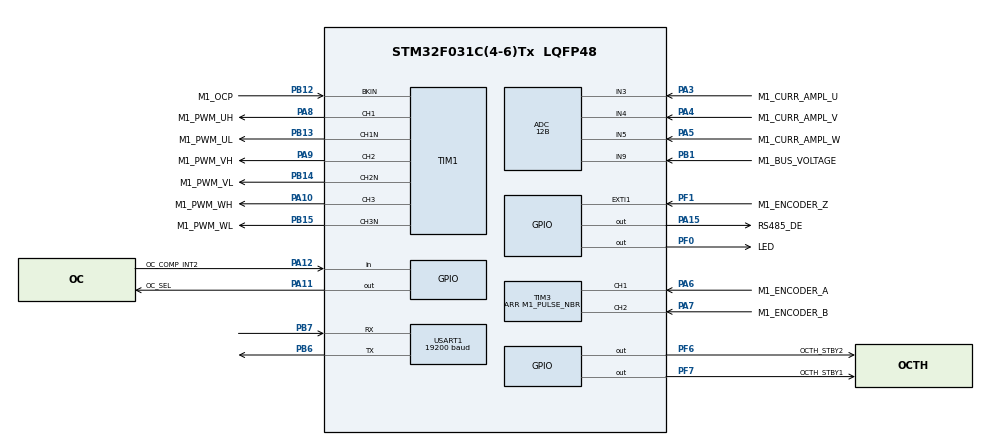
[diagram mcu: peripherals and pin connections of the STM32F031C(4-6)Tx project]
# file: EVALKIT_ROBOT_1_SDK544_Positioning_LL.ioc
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ADC.ClockPrescaler=ADC_CLOCK_ASYNC_DIV1
ADC.ContinuousConvMode=DISABLE
ADC.DMAContinuousRequests=ENABLE
ADC.DataAlign=ADC_DATAALIGN_LEFT
ADC.DiscontinuousConvMode=DISABLE
ADC.EOCSelection=ADC_EOC_SINGLE_CONV
ADC.EnableAnalogWatchDog=false
ADC.ExternalTrigConv=ADC_EXTERNALTRIGCONV_T1_TRGO
ADC.ExternalTrigConvEdge=ADC_EXTERNALTRIGCONVEDGE_RISING
ADC.LowPowerAutoPowerOff=DISABLE
ADC.LowPowerAutoWait=DISABLE
ADC.Overrun=ADC_OVR_DATA_PRESERVED
ADC.Resolution=ADC_RESOLUTION_12B
ADC.SamplingTime=ADC_SAMPLETIME_7CYCLES_5
ADC.ScanConvMode=ADC_SCAN_DIRECTION_FORWARD
Dma.ADC.0.Direction=DMA_PERIPH_TO_MEMORY
Dma.ADC.0.Instance=DMA1_Channel1
Dma.ADC.0.MemDataAlignment=DMA_MDATAALIGN_HALFWORD
Dma.ADC.0.MemInc=DMA_MINC_ENABLE
Dma.ADC.0.Mode=DMA_CIRCULAR
Dma.ADC.0.PeriphDataAlignment=DMA_PDATAALIGN_HALFWORD
Dma.ADC.0.PeriphInc=DMA_PINC_DISABLE
Dma.ADC.0.Priority=DMA_PRIORITY_HIGH
Dma.Request0=ADC
ExtraMW=MotorControl
ExtraMW.MotorControl.Config=MotorControl
ExtraMW.MotorControl.Mode=MotorControl
ExtraMW.MotorControl.Root=MCSDK_v5.4.4/MotorControl
ExtraMW.MotorControl.Template=templates
Mcu.Family=STM32F0
Mcu.Name=STM32F031C(4-6)Tx
Mcu.Package=LQFP48
MotorControl.ADC_1_PERIPH=ADC1
MotorControl.ADC_2_PERIPH=ADC2
MotorControl.ADC_AHBPERIPH=RCC_AHBPeriph_ADC12
MotorControl.ADC_CLOCK_WB_DIV=1
MotorControl.ADC_CLOCK_WB_FREQ=12
MotorControl.ADC_PERIPH=ADC1
MotorControl.ADC_REFERENCE_VOLTAGE=3.30
MotorControl.ALIGNMENT_ANGLE_DEG=0
MotorControl.ALIGNMENT_DURATION=700
MotorControl.AMPLIFICATION_GAIN=4.38
MotorControl.ANGC={0,0,0,0,0,0,0,0}
MotorControl.BEMF_CONSISTENCY_GAIN=64
MotorControl.BEMF_CONSISTENCY_TOL=64
MotorControl.BKIN1_FILTER=0
MotorControl.BKIN2_FILTER=0
MotorControl.BKIN2_MODE=NONE
MotorControl.BKIN_MODE=EXT_MODE
MotorControl.BOARD=CUSTOM
MotorControl.BRKIN2_GPIO_AF=GPIO_AF_2
MotorControl.BRKIN_GPIO_AF=GPIO_AF_2
MotorControl.BUS_VOLTAGE_READING=true
MotorControl.CCMRAM_ENABLED=false
MotorControl.CLOCK_FREQUENCY=CPU_CLK_48_MHZ
MotorControl.CLOCK_SOURCE=INTERNAL
MotorControl.CONSTANT1_D=25086
MotorControl.CONSTANT1_Q=25086
MotorControl.CONSTANT2_QD=17556
MotorControl.CORD_BEMF_CONSISTENCY_GAIN=64
MotorControl.CORD_BEMF_CONSISTENCY_TOL=64
MotorControl.CORD_F1=8192
MotorControl.CORD_F2=16384
MotorControl.CORD_FIFO_DEPTH_01HZ=64
MotorControl.CORD_FIFO_DEPTH_DPP=64
MotorControl.CORD_GAIN1=-11637
MotorControl.CORD_GAIN2=5027
MotorControl.CORD_MAX_ACCEL_DPPP=187
MotorControl.CORD_MEAS_ERRORS_BEFORE_FAULTS=3
MotorControl.CORD_VARIANCE_THRESHOLD=4
MotorControl.CPU_CLK_48_MHZ=true
MotorControl.CTRBDID=10010
MotorControl.CUBE_MX_VER=5.6.1
MotorControl.CURRENT_READING_TOPOLOGY=THREE_SHUNT
MotorControl.CURR_SAMPLING_TIME=7
MotorControl.DAC_EMULATED=false
MotorControl.DAC_FUNCTIONALITY=false
MotorControl.DAC_TIMER_CH1_GPIO_PIN=LL_GPIO_PIN_0
MotorControl.DAC_TIMER_CH1_GPIO_PORT=GPIOA
MotorControl.DAC_TIMER_CH2_GPIO_PIN=LL_GPIO_PIN_0
MotorControl.DAC_TIMER_CH2_GPIO_PORT=GPIOA
MotorControl.DAC_TIMER_SELECTION=TIM14
MotorControl.DC_CURRENT_RS_MEAS=2.72
MotorControl.DEBUG_DAC_CH1=false
MotorControl.DEBUG_DAC_CH2=false
MotorControl.DEFAULT_CONTROL_MODE=STC_SPEED_MODE
MotorControl.DEFAULT_DAC_CHANNEL_1=MC_PROTOCOL_REG_I_A
MotorControl.DEFAULT_DAC_CHANNEL_2=MC_PROTOCOL_REG_I_B
MotorControl.DEFAULT_DAC_MOTOR=0
MotorControl.DEFAULT_FLUX_COMPONENT=0
MotorControl.DEFAULT_TARGET_SPEED_RPM=500
MotorControl.DEFAULT_TORQUE_COMPONENT=0
MotorControl.DISSIPATIVE_BRAKE_POLARITY=DOUT_ACTIVE_HIGH
MotorControl.DRIVES_NUMBER_SELECTION=SINGLEDRIVE
MotorControl.EMERGENCY2_STOP_GPIO_PIN=LL_GPIO_PIN_12
MotorControl.EMERGENCY2_STOP_GPIO_PORT=GPIOB
MotorControl.EMERGENCY_STOP_GPIO_PIN=LL_GPIO_PIN_12
MotorControl.EMERGENCY_STOP_GPIO_PORT=GPIOB
MotorControl.ENABLE_SL_ALGO_FROM_PHASE=2
MotorControl.ENCODER=true
MotorControl.ENCODER_AVAILABLE=true
MotorControl.ENCODER_PPR=1024
MotorControl.ENC_AVERAGING_FIFO_DEPTH=16
MotorControl.ENC_A_GPIO_PIN=LL_GPIO_PIN_6
MotorControl.ENC_A_GPIO_PORT=GPIOA
MotorControl.ENC_B_GPIO_PIN=LL_GPIO_PIN_7
MotorControl.ENC_B_GPIO_PORT=GPIOA
MotorControl.ENC_ICx_FILTER=32
MotorControl.ENC_INVERT_SPEED=false
MotorControl.ENC_MEAS_ERRORS_BEFORE_FAULTS=3
MotorControl.ENC_TIMER_REMAPPING=NO_REMAP_TIM3
MotorControl.ENC_TIMER_SELECTION=ENC_TIM3
MotorControl.ENC_USE_CH3=true
MotorControl.ENC_Z_GPIO_PIN=LL_GPIO_PIN_0
MotorControl.ENC_Z_GPIO_PORT=GPIOB
MotorControl.EXT_CLOCK_FREQUENCY=INT_RC_OSC
MotorControl.F1=8192
MotorControl.F2=16384
MotorControl.FEEDBACK_NET_FILTERING=false
MotorControl.FEED_FORWARD_CURRENT_REG_ENABLING=false
MotorControl.FINAL_I_ALIGNMENT=13047
MotorControl.FLUX_WEAKENING_ENABLING=false
MotorControl.FW_KIDIV=32768
MotorControl.FW_KI_GAIN=5000
MotorControl.FW_KPDIV=32768
MotorControl.FW_KP_GAIN=3000
MotorControl.FW_VOLTAGE_REF=985
MotorControl.GAIN1=-11637
MotorControl.GAIN2=5027
MotorControl.H1_GPIO_PIN=LL_GPIO_PIN_0
MotorControl.H1_GPIO_PORT=GPIOA
MotorControl.H2_GPIO_PIN=LL_GPIO_PIN_1
MotorControl.H2_GPIO_PORT=GPIOA
MotorControl.H3_GPIO_PIN=LL_GPIO_PIN_2
MotorControl.H3_GPIO_PORT=GPIOA
MotorControl.HALL_AVERAGING_FIFO_DEPTH=6
MotorControl.HALL_ICx_FILTER=62
MotorControl.HALL_MEAS_ERRORS_BEFORE_FAULTS=3
MotorControl.HALL_MTPA=false
MotorControl.HALL_PHASE_SHIFT=300
MotorControl.HALL_SENSORS_AVAILABLE=true
MotorControl.HALL_SENSORS_PLACEMENT=DEGREES_120
MotorControl.HALL_TIMER_REMAPPING=NO_REMAP_TIM2
MotorControl.HALL_TIMER_SELECTION=HALL_TIM2
MotorControl.HFI_AMPLITUDE=25
MotorControl.HFI_DC_0_COEFF=0.00146
MotorControl.HFI_DC_1_COEFF=0.002921
MotorControl.HFI_DC_2_COEFF=0.00146
MotorControl.HFI_DC_3_COEFF=1.889033
MotorControl.HFI_DC_4_COEFF=-0.894874
MotorControl.HFI_DEBUG_MODE=false
MotorControl.HFI_FREQUENCY=400
MotorControl.HFI_HIFRAMPLSCAN=25
MotorControl.HFI_HP_ID_0_COEFF=0.901513
MotorControl.HFI_HP_ID_1_COEFF=-1.803026
MotorControl.HFI_HP_ID_2_COEFF=0.901513
MotorControl.HFI_HP_ID_3_COEFF=1.793303
MotorControl.HFI_HP_ID_4_COEFF=-0.81275
MotorControl.HFI_IDH_DELAY=32400
MotorControl.HFI_LOCKFREQ=55
MotorControl.HFI_LP_ID_0_COEFF=0.015476
MotorControl.HFI_LP_ID_1_COEFF=0.030952
MotorControl.HFI_LP_ID_2_COEFF=0.015476
MotorControl.HFI_LP_ID_3_COEFF=1.61855
MotorControl.HFI_LP_ID_4_COEFF=-0.680453
MotorControl.HFI_MAXANGLEDIFF=3640
MotorControl.HFI_MINIMUM_SPEED_RPM=402
MotorControl.HFI_NOTCH_IQD_0_COEFF=0.95059
MotorControl.HFI_NOTCH_IQD_1_COEFF=-1.859635
MotorControl.HFI_NOTCH_IQD_2_COEFF=0.95059
MotorControl.HFI_NOTCH_IQD_3_COEFF=1.859635
MotorControl.HFI_NOTCH_IQD_4_COEFF=-0.901181
MotorControl.HFI_NSDETPOINTSSKIP=10
MotorControl.HFI_NSMAXDETPOINTS=20
MotorControl.HFI_NS_MIN_SAT_DIFF=0
MotorControl.HFI_PID_KIDIV=32768
MotorControl.HFI_PID_KI_DEFAULT=400
MotorControl.HFI_PID_KPDIV=16384
MotorControl.HFI_PID_KP_DEFAULT=800
MotorControl.HFI_PLL_KI_DEFAULT=0.00400
MotorControl.HFI_PLL_KP_DEFAULT=0.00060
MotorControl.HFI_RESTARTTIMESEC=0.1
MotorControl.HFI_RESTART_RPM_TH=(((HFI_STO_RPM_TH)+(STO_HFI_RPM_TH))/2)
MotorControl.HFI_REVERT_DIRECTION=true
MotorControl.HFI_SCANROTATIONSNO=3
MotorControl.HFI_SPD_BUFFER_DEPTH_01HZ=64
MotorControl.HFI_STEPANGLE=3640
MotorControl.HFI_STO_RPM_TH=OBS_MINIMUM_SPEED_RPM
MotorControl.HFI_WAITAFTERNS2=4
MotorControl.HFI_WAITBEFORESN=6
MotorControl.HFI_WAITSYNCH=20
MotorControl.HFI_WAITTRACK=20
MotorControl.HIGH_SIDE_BRAKE_STATE=false
MotorControl.HIGH_SIDE_IDLE_STATE=false
MotorControl.HW_COMPLEMENTED_LOW_SIDE=false
MotorControl.HW_DEAD_TIME_NS=100
MotorControl.HW_OV_CURRENT_PROT_BYPASS=false
MotorControl.ID_DEMAG=-23658
MotorControl.INRUSH_CURRLIMIT_AT_POWER_ON=true
MotorControl.INRUSH_CURRLIMIT_CHANGE_AFTER_MS=1000
MotorControl.INRUSH_CURRLIMIT_ENABLING=false
MotorControl.INRUSH_CURRLIMIT_GPIO_PIN=LL_GPIO_PIN_4
MotorControl.INRUSH_CURRLIMIT_GPIO_PORT=GPIOE
MotorControl.INRUSH_CURR_LIMITER_POLARITY=DOUT_ACTIVE_HIGH
MotorControl.INTERNAL_OVERCURRENTPROTECTION=false
MotorControl.INTERNAL_OVERVOLTAGEPROTECTION=false
MotorControl.INT_RC_OSC=true
MotorControl.IPs=NVIC,RCC,SYS,MotorControl,TIM1,ADC,DMA,TIM3
MotorControl.IQMAX=23658
MotorControl.LCD_JOYSTICK_FUNCTIONALITY=false
MotorControl.LCD_MODE=LCD_FULL
MotorControl.LDLQ_RATIO=1.000
MotorControl.LOW_SIDE_BRAKE_STATE=false
MotorControl.LOW_SIDE_IDLE_STATE=false
MotorControl.LOW_SIDE_SIGNALS_ENABLING=LS_PWM_TIMER
MotorControl.LS=0.000338
MotorControl.MAX_APPLICATION_SPEED=4550
MotorControl.MAX_MODULATION_100_PER_CENT=true
MotorControl.MAX_MODULATION_INDEX=MAX_MODULATION_100_PER_CENT
MotorControl.MCU=STSPIN32F0A
MotorControl.MCU_TYPE=STSPIN32F0A
MotorControl.MC_WORKBENCH_VERSION=5.4.4.20160
MotorControl.MEAS_ERRORS_BEFORE_FAULTS=3
MotorControl.MIN_APPLICATION_SPEED=0
MotorControl.MOTOR_MAX_SPEED_RPM=4550
MotorControl.MOTOR_TYPE=PMSM
MotorControl.MOTOR_VOLTAGE_CONSTANT=6.4
MotorControl.MTPA_ENABLING=false
MotorControl.NB_CONSECUTIVE_TESTS=2
MotorControl.NOMINAL_BUS_VOLTAGE_V=36
MotorControl.NOMINAL_CURRENT=23658
MotorControl.OBS_MEAS_ERRORS_BEFORE_FAULTS=3
MotorControl.OBS_MINIMUM_SPEED_RPM=886
MotorControl.OCPA_INVERTINGINPUT=COMPX_InvertingInput_VREF
MotorControl.OCPA_INVERTINGINPUT_GPIO_PIN=LL_GPIO_PIN_4
MotorControl.OCPA_INVERTINGINPUT_GPIO_PORT=GPIOA
MotorControl.OCPA_INVERTINGINPUT_MODE=INT_MODE
MotorControl.OCPA_NONINVERTINGINPUT=COMP1_NonInvertingInput_PA1
MotorControl.OCPA_NONINVERTINGINPUT_GPIO_PIN=LL_GPIO_PIN_1
MotorControl.OCPA_NONINVERTINGINPUT_GPIO_PORT=GPIOA
MotorControl.OCPA_OUTPUT=COMP_Output_TIM1BKIN2
MotorControl.OCPA_OUTPUTPOL=COMP_OutputPol_NonInverted
MotorControl.OCPA_OUTPUT_GPIO_AF=GPIO_AF_2
MotorControl.OCPA_OUTPUT_GPIO_PIN=LL_GPIO_PIN_0
MotorControl.OCPA_OUTPUT_GPIO_PORT=GPIOA
MotorControl.OCPA_OUTPUT_MODE=INT_MODE
MotorControl.OCPA_SELECTION=COMP1
MotorControl.OCPB_INVERTINGINPUT=COMPX_InvertingInput_VREF
MotorControl.OCPB_INVERTINGINPUT_GPIO_PIN=LL_GPIO_PIN_4
MotorControl.OCPB_INVERTINGINPUT_GPIO_PORT=GPIOA
MotorControl.OCPB_INVERTINGINPUT_MODE=INT_MODE
MotorControl.OCPB_NONINVERTINGINPUT=COMP2_NonInvertingInput_PA7
MotorControl.OCPB_NONINVERTINGINPUT_GPIO_PIN=LL_GPIO_PIN_7
MotorControl.OCPB_NONINVERTINGINPUT_GPIO_PORT=GPIOA
MotorControl.OCPB_OUTPUT=COMP_Output_TIM1BKIN2
MotorControl.OCPB_OUTPUTPOL=COMP_OutputPol_NonInverted
MotorControl.OCPB_OUTPUT_GPIO_AF=GPIO_AF_2
MotorControl.OCPB_OUTPUT_GPIO_PIN=LL_GPIO_PIN_2
MotorControl.OCPB_OUTPUT_GPIO_PORT=GPIOA
MotorControl.OCPB_OUTPUT_MODE=INT_MODE
MotorControl.OCPB_SELECTION=COMP2
MotorControl.OCPC_INVERTINGINPUT=COMPX_InvertingInput_VREF
MotorControl.OCPC_INVERTINGINPUT_GPIO_PIN=LL_GPIO_PIN_4
MotorControl.OCPC_INVERTINGINPUT_GPIO_PORT=GPIOA
MotorControl.OCPC_INVERTINGINPUT_MODE=INT_MODE
MotorControl.OCPC_NONINVERTINGINPUT=COMP3_NonInvertingInput_PB14
MotorControl.OCPC_NONINVERTINGINPUT_GPIO_PIN=LL_GPIO_PIN_14
MotorControl.OCPC_NONINVERTINGINPUT_GPIO_PORT=GPIOB
MotorControl.OCPC_OUTPUT=COMP_Output_TIM1BKIN2
MotorControl.OCPC_OUTPUTPOL=COMP_OutputPol_NonInverted
MotorControl.OCPC_OUTPUT_GPIO_AF=GPIO_AF_2
MotorControl.OCPC_OUTPUT_GPIO_PIN=LL_GPIO_PIN_8
MotorControl.OCPC_OUTPUT_GPIO_PORT=GPIOC
MotorControl.OCPC_OUTPUT_MODE=INT_MODE
MotorControl.OCPC_SELECTION=COMP3
MotorControl.OCPREF=23830
MotorControl.OCP_COMP_THRESHOLD=0.50
MotorControl.OCP_FILTER=COMP_Mode_HighSpeed
MotorControl.OCP_INVERTINGINPUT=COMPX_InvertingInput_VREF
MotorControl.OCP_INVERTINGINPUT_GPIO_PIN=LL_GPIO_PIN_4
MotorControl.OCP_INVERTINGINPUT_GPIO_PORT=GPIOA
MotorControl.OCP_INVERTINGINPUT_MODE=INT_MODE
MotorControl.OCP_NONINVERTINGINPUT=COMP2_NonInvertingInput_PA7
MotorControl.OCP_NONINVERTINGINPUT_GPIO_PIN=LL_GPIO_PIN_7
MotorControl.OCP_NONINVERTINGINPUT_GPIO_PORT=GPIOA
MotorControl.OCP_OUTPUT=COMP_Output_TIM1BKIN2
MotorControl.OCP_OUTPUTPOL=COMP_OutputPol_NonInverted
MotorControl.OCP_OUTPUT_GPIO_AF=GPIO_AF_2
MotorControl.OCP_OUTPUT_GPIO_PIN=LL_GPIO_PIN_2
MotorControl.OCP_OUTPUT_GPIO_PORT=GPIOA
MotorControl.OCP_OUTPUT_MODE=INT_MODE
MotorControl.OCP_SELECTION=COMP2
MotorControl.OFST={0,0,0,0,0,0,0,0}
MotorControl.ON_OVER_VOLTAGE=TURN_OFF_PWM
MotorControl.OPAMP1_INVERTINGINPUT=OPAMP1_InvertingInput_PGA
MotorControl.OPAMP1_INVERTINGINPUT_GPIO_PIN=LL_GPIO_PIN_3
MotorControl.OPAMP1_INVERTINGINPUT_GPIO_PORT=GPIOA
MotorControl.OPAMP1_INVERTINGINPUT_MODE=INT_MODE
MotorControl.OPAMP1_NONINVERTINGINPUT_PHA=OPAMP1_NonInvertingInput_PA1
MotorControl.OPAMP1_NONINVERTINGINPUT_PHA_GPIO_PIN=LL_GPIO_PIN_1
MotorControl.OPAMP1_NONINVERTINGINPUT_PHA_GPIO_PORT=GPIOA
MotorControl.OPAMP1_NONINVERTINGINPUT_PHB=OPAMP1_NonInvertingInput_PA7
MotorControl.OPAMP1_NONINVERTINGINPUT_PHB_GPIO_PIN=LL_GPIO_PIN_7
MotorControl.OPAMP1_NONINVERTINGINPUT_PHB_GPIO_PORT=GPIOA
MotorControl.OPAMP1_OUT_GPIO_PIN=LL_GPIO_PIN_2
MotorControl.OPAMP1_OUT_GPIO_PORT=GPIOA
MotorControl.OPAMP1_SELECTION=OPAMP1
MotorControl.OPAMP2_INVERTINGINPUT=OPAMP2_InvertingInput_PGA
MotorControl.OPAMP2_INVERTINGINPUT_GPIO_PIN=LL_GPIO_PIN_5
MotorControl.OPAMP2_INVERTINGINPUT_GPIO_PORT=GPIOC
MotorControl.OPAMP2_INVERTINGINPUT_MODE=INT_MODE
MotorControl.OPAMP2_NONINVERTINGINPUT_PHA=OPAMP2_NonInvertingInput_PB14
MotorControl.OPAMP2_NONINVERTINGINPUT_PHA_GPIO_PIN=LL_GPIO_PIN_14
MotorControl.OPAMP2_NONINVERTINGINPUT_PHA_GPIO_PORT=GPIOB
MotorControl.OPAMP2_NONINVERTINGINPUT_PHB=OPAMP2_NonInvertingInput_PA7
MotorControl.OPAMP2_NONINVERTINGINPUT_PHB_GPIO_PIN=LL_GPIO_PIN_7
MotorControl.OPAMP2_NONINVERTINGINPUT_PHB_GPIO_PORT=GPIOA
MotorControl.OPAMP2_NONINVERTINGINPUT_PHC=OPAMP2_NonInvertingInput_PB14
MotorControl.OPAMP2_NONINVERTINGINPUT_PHC_GPIO_PIN=LL_GPIO_PIN_14
MotorControl.OPAMP2_NONINVERTINGINPUT_PHC_GPIO_PORT=GPIOB
MotorControl.OPAMP2_OUT_GPIO_PIN=LL_GPIO_PIN_6
MotorControl.OPAMP2_OUT_GPIO_PORT=GPIOA
MotorControl.OPAMP2_SELECTION=OPAMP2
MotorControl.OPAMP3_INVERTINGINPUT=OPAMP1_InvertingInput_PGA
MotorControl.OPAMP3_INVERTINGINPUT_GPIO_PIN=LL_GPIO_PIN_0
MotorControl.OPAMP3_INVERTINGINPUT_GPIO_PORT=GPIOA
MotorControl.OPAMP3_INVERTINGINPUT_MODE=INT_MODE
MotorControl.OPAMP3_SELECTION=OPAMP1
MotorControl.OPAMP_INVERTINGINPUT=OPAMP1_InvertingInput_PGA
MotorControl.OPAMP_INVERTINGINPUT_GPIO_PIN=LL_GPIO_PIN_3
MotorControl.OPAMP_INVERTINGINPUT_GPIO_PORT=GPIOA
MotorControl.OPAMP_INVERTINGINPUT_MODE=INT_MODE
MotorControl.OPAMP_NONINVERTINGINPUT=OPAMP1_NonInvertingInput_PA7
MotorControl.OPAMP_NONINVERTINGINPUT_GPIO_PIN=LL_GPIO_PIN_7
MotorControl.OPAMP_NONINVERTINGINPUT_GPIO_PORT=GPIOA
MotorControl.OPAMP_OUT_GPIO_PIN=LL_GPIO_PIN_2
MotorControl.OPAMP_OUT_GPIO_PORT=GPIOA
MotorControl.OPAMP_PGACONNECT=OPAMP_PGAConnect_No
MotorControl.OPAMP_PGAGAIN=OPAMP_OPAMP_PGAGain_2
MotorControl.OPAMP_SELECTION=OPAMP1
MotorControl.OPAMP_TYPE_GAIN=INTERNAL
MotorControl.OPEN_LOOP_FOC=false
MotorControl.OPEN_LOOP_K=44
MotorControl.OPEN_LOOP_OFF=4400
MotorControl.OPEN_LOOP_SPEED_RAMP_DURATION_MS=1000
MotorControl.OPEN_LOOP_SPEED_RPM=100
MotorControl.OPEN_LOOP_VF=false
MotorControl.OPEN_LOOP_VOLTAGE_d=6000
MotorControl.OVERCURR_FEEDBACK_POLARITY=EMSTOP_ACTIVE_HIGH
MotorControl.OVERCURR_PROTECTION_HW_DISABLING=DOUT_ACTIVE_HIGH
MotorControl.OVPREF=23830
MotorControl.OVP_FILTER=COMP_Mode_HighSpeed
MotorControl.OVP_INVERTINGINPUT=COMPX_InvertingInput_VREF
MotorControl.OVP_INVERTINGINPUT_GPIO_PIN=LL_GPIO_PIN_4
MotorControl.OVP_INVERTINGINPUT_GPIO_PORT=GPIOA
MotorControl.OVP_INVERTINGINPUT_MODE=INT_MODE
MotorControl.OVP_NONINVERTINGINPUT=COMP7_NonInvertingInput_PA0
MotorControl.OVP_NONINVERTINGINPUT_GPIO_PIN=LL_GPIO_PIN_0
MotorControl.OVP_NONINVERTINGINPUT_GPIO_PORT=GPIOA
MotorControl.OVP_OUTPUT=COMP_Output_TIM1BKIN
MotorControl.OVP_OUTPUTPOL=COMP_OutputPol_NonInverted
MotorControl.OVP_OUTPUT_GPIO_AF=GPIO_AF_2
MotorControl.OVP_OUTPUT_GPIO_PIN=LL_GPIO_PIN_2
MotorControl.OVP_OUTPUT_GPIO_PORT=GPIOC
MotorControl.OVP_OUTPUT_MODE=INT_MODE
MotorControl.OVP_SELECTION=COMP7
MotorControl.OV_CURR_BYPASS_GPIO_PIN=LL_GPIO_PIN_5
MotorControl.OV_CURR_BYPASS_GPIO_PORT=GPIOE
MotorControl.OV_TEMPERATURE_HYSTERESIS_C=10
MotorControl.OV_TEMPERATURE_PROT_ENABLING=false
MotorControl.OV_TEMPERATURE_THRESHOLD_C=70
MotorControl.OV_VOLTAGE_PROT_ENABLING=true
MotorControl.OV_VOLTAGE_THRESHOLD_V=44
MotorControl.PHASE1_DURATION=1000
MotorControl.PHASE1_FINAL_CURRENT=13047
MotorControl.PHASE1_FINAL_SPEED_RPM=0
MotorControl.PHASE2_DURATION=1968
MotorControl.PHASE2_FINAL_CURRENT=13047
MotorControl.PHASE2_FINAL_SPEED_RPM=984
MotorControl.PHASE3_DURATION=0
MotorControl.PHASE3_FINAL_CURRENT=13047
MotorControl.PHASE3_FINAL_SPEED_RPM=984
MotorControl.PHASE4_DURATION=0
MotorControl.PHASE4_FINAL_CURRENT=13047
MotorControl.PHASE4_FINAL_SPEED_RPM=984
MotorControl.PHASE5_DURATION=0
MotorControl.PHASE5_FINAL_CURRENT=13047
MotorControl.PHASE5_FINAL_SPEED_RPM=984
MotorControl.PHASE_CURRENTS_ADC=ADC1_2
MotorControl.PHASE_CURRENTS_CHANNEL=ADC_CHANNEL_9
MotorControl.PHASE_CURRENTS_GPIO_PIN=LL_GPIO_PIN_0
MotorControl.PHASE_CURRENTS_GPIO_PORT=GPIOA
MotorControl.PHASE_UH_GPIO_AF=GPIO_AF_2
MotorControl.PHASE_UH_GPIO_PIN=LL_GPIO_PIN_8
MotorControl.PHASE_UH_GPIO_PORT=GPIOA
MotorControl.PHASE_UH_POLARITY=H_ACTIVE_HIGH
MotorControl.PHASE_UL_GPIO_AF=GPIO_AF_2
MotorControl.PHASE_UL_GPIO_PIN=LL_GPIO_PIN_13
MotorControl.PHASE_UL_GPIO_PORT=GPIOB
MotorControl.PHASE_UL_POLARITY=L_ACTIVE_HIGH
MotorControl.PHASE_U_CURR_ADC=ADC1
MotorControl.PHASE_U_CURR_CHANNEL=ADC_CHANNEL_3
MotorControl.PHASE_U_GPIO_PIN=LL_GPIO_PIN_3
MotorControl.PHASE_U_GPIO_PORT=GPIOA
MotorControl.PHASE_VH_GPIO_AF=GPIO_AF_2
MotorControl.PHASE_VH_GPIO_PIN=LL_GPIO_PIN_9
MotorControl.PHASE_VH_GPIO_PORT=GPIOA
MotorControl.PHASE_VH_POLARITY=H_ACTIVE_HIGH
MotorControl.PHASE_VL_GPIO_AF=GPIO_AF_2
MotorControl.PHASE_VL_GPIO_PIN=LL_GPIO_PIN_14
MotorControl.PHASE_VL_GPIO_PORT=GPIOB
MotorControl.PHASE_VL_POLARITY=L_ACTIVE_HIGH
MotorControl.PHASE_V_CURR_ADC=ADC1
MotorControl.PHASE_V_CURR_CHANNEL=ADC_CHANNEL_4
MotorControl.PHASE_V_GPIO_PIN=LL_GPIO_PIN_4
MotorControl.PHASE_V_GPIO_PORT=GPIOA
MotorControl.PHASE_WH_GPIO_AF=GPIO_AF_2
MotorControl.PHASE_WH_GPIO_PIN=LL_GPIO_PIN_10
MotorControl.PHASE_WH_GPIO_PORT=GPIOA
MotorControl.PHASE_WH_POLARITY=H_ACTIVE_HIGH
MotorControl.PHASE_WL_GPIO_AF=GPIO_AF_2
MotorControl.PHASE_WL_GPIO_PIN=LL_GPIO_PIN_15
MotorControl.PHASE_WL_GPIO_PORT=GPIOB
MotorControl.PHASE_WL_POLARITY=L_ACTIVE_HIGH
MotorControl.PHASE_W_CURR_ADC=ADC1
MotorControl.PHASE_W_CURR_CHANNEL=ADC_CHANNEL_5
MotorControl.PHASE_W_GPIO_PIN=LL_GPIO_PIN_5
MotorControl.PHASE_W_GPIO_PORT=GPIOA
MotorControl.PID_FLUX_KD_DEFAULT=100
MotorControl.PID_FLUX_KI_DEFAULT=246
MotorControl.PID_FLUX_KP_DEFAULT=2318
MotorControl.PID_SPEED_KD_DEFAULT=0
MotorControl.PID_SPEED_KI_DEFAULT=960
MotorControl.PID_SPEED_KP_DEFAULT=2902
MotorControl.PID_TORQUE_KD_DEFAULT=100
MotorControl.PID_TORQUE_KI_DEFAULT=246
MotorControl.PID_TORQUE_KP_DEFAULT=2318
MotorControl.PLL_KI_GAIN=83
MotorControl.PLL_KP_GAIN=1412
MotorControl.POLE_PAIR_NUM=7
MotorControl.POSITION_CTRL_ENABLING=true
MotorControl.POSITION_CTRL_KDDIV=16
MotorControl.POSITION_CTRL_KD_GAIN=1000
MotorControl.POSITION_CTRL_KIDIV=32768
MotorControl.POSITION_CTRL_KI_GAIN=1000
MotorControl.POSITION_CTRL_KPDIV=1024
MotorControl.POSITION_CTRL_KP_GAIN=10000
MotorControl.POSITION_LOOP_FREQUENCY_HZ=1000
MotorControl.PWBDID=10010
MotorControl.PWM_FREQUENCY=12000
MotorControl.PWM_TIMER_REMAPPING=PWM_NO_REMAP
MotorControl.PWM_TIMER_SELECTION=PWM_TIM1
MotorControl.REGCONVADC=ADC1
MotorControl.REGULATION_EXECUTION_RATE=1
MotorControl.RS=0.43
MotorControl.RSHUNT=0.10000
MotorControl.RTOS=NONE
MotorControl.R_BRAKE_GPIO_PIN=LL_GPIO_PIN_5
MotorControl.R_BRAKE_GPIO_PORT=GPIOE
MotorControl.R_BRAKE_SWITCH_OFF_THRES_V=35
MotorControl.SEGDIV=0
MotorControl.SERIAL_COMMUNICATION=false
MotorControl.SERIAL_COM_CHANNEL1=MC_PROTOCOL_REG_I_A
MotorControl.SERIAL_COM_CHANNEL2=MC_PROTOCOL_REG_I_A
MotorControl.SERIAL_COM_MODE=COM_BIDIRECTIONAL
MotorControl.SERIAL_COM_MOTOR=0
MotorControl.SHARED_SIGNAL_ENABLE=false
MotorControl.SINGLEDRIVE=true
MotorControl.SPD_DIFFERENTIAL_TERM_ENABLING=false
MotorControl.SPEED_BAND_LOWER_LIMIT=15
MotorControl.SPEED_BAND_UPPER_LIMIT=17
MotorControl.SPEED_SENSOR_SELECTION=ENCODER
MotorControl.SP_KDDIV=16
MotorControl.SP_KIDIV=16384
MotorControl.SP_KPDIV=128
MotorControl.STARTING_ANGLE_DEG=0
MotorControl.START_STOP_BTN=false
MotorControl.START_STOP_GPIO_PIN=LL_GPIO_PIN_0
MotorControl.START_STOP_GPIO_PORT=GPIOF
MotorControl.START_STOP_POLARITY=DIN_ACTIVE_LOW
MotorControl.START_STOP_POLARITY_EDGE=GPIO_PULLUP
MotorControl.STO_FIFO_DEPTH_01HZ=64
MotorControl.STO_FIFO_DEPTH_DPP=64
MotorControl.STO_HFI_RPM_TH=460
MotorControl.STSPIN32F0A=true
MotorControl.SW_DEADTIME_NS=300
MotorControl.SW_OV_CURRENT_PROT_ENABLING=true
MotorControl.T0_C=25
MotorControl.TEMPERATURE_READING=false
MotorControl.TEMP_ADC_SAMPLING_TIME=1
MotorControl.TEMP_FDBK_ADC=ADC1
MotorControl.TEMP_FDBK_CHANNEL=ADC_CHANNEL_5
MotorControl.TEMP_FDBK_GPIO_PIN=LL_GPIO_PIN_5
MotorControl.TEMP_FDBK_GPIO_PORT=GPIOA
MotorControl.TFDIFFERENTIAL_TERM_ENABLING=false
MotorControl.TF_KDDIV=8192
MotorControl.TF_KIDIV=16384
MotorControl.TF_KPDIV=16384
MotorControl.THREE_SHUNT=true
MotorControl.TNOISE_NS=800
MotorControl.TRANSITION_DURATION=25
MotorControl.TRISE_NS=800
MotorControl.T_MAX=70
MotorControl.UD_VOLTAGE_THRESHOLD_V=28
MotorControl.USART_REMAPPING=NO_REMAP_USART1
MotorControl.USART_RX_GPIO_PIN=LL_GPIO_PIN_7
MotorControl.USART_RX_GPIO_PORT=GPIOB
MotorControl.USART_SELECTION=USE_USART1
MotorControl.USART_SPEED=9600
MotorControl.USART_TX_GPIO_PIN=LL_GPIO_PIN_6
MotorControl.USART_TX_GPIO_PORT=GPIOB
MotorControl.USE_3OPAMPS=false
MotorControl.USE_INTERNAL_OPAMP=false
MotorControl.UV_VOLTAGE_PROT_ENABLING=true
MotorControl.V0_V=0.290
MotorControl.VARIANCE_THRESHOLD=0.1
MotorControl.VBUS_ADC=ADC1
MotorControl.VBUS_ADC_SAMPLING_TIME=28
MotorControl.VBUS_CHANNEL=ADC_CHANNEL_9
MotorControl.VBUS_GPIO_PIN=LL_GPIO_PIN_1
MotorControl.VBUS_GPIO_PORT=GPIOB
MotorControl.VBUS_PARTITIONING_FACTOR=0.0526
MotorControl.WB_to_Mx_template_version=20-04-17
MotorControl.WB_to_Mx_version=1.1.0
MotorControl.dV_dT=0.025
NVIC.DMA1_Channel1_IRQn=true\:1\:0\:true\:true\:false\:2\:true\:true
NVIC.EXTI0_1_IRQn=true\:3\:0\:false\:true\:false\:4\:true\:true
NVIC.TIM14_IRQn=true\:2\:0\:true\:true\:true\:5\:true\:false
NVIC.TIM16_IRQn=true\:2\:0\:true\:true\:true\:6\:true\:false
NVIC.TIM1_BRK_UP_TRG_COM_IRQn=true\:0\:0\:false\:true\:false\:1\:true\:true
NVIC.TIM3_IRQn=true\:3\:0\:false\:true\:false\:3\:true\:true
NVIC.USART1_IRQn=true\:3\:0\:true\:true\:true\:7\:true\:false
PA10.GPIO_Label=M1_PWM_WH
PA10.GPIO_PuPd=GPIO_PULLDOWN
PA10.GPIO_Speed=GPIO_SPEED_FREQ_HIGH
PA10.Signal=S_TIM1_CH3
PA11.GPIO_Label=OC_SEL
PA11.GPIO_PuPd=GPIO_PULLDOWN
PA11.PinState=GPIO_PIN_SET
PA11.Signal=GPIO_Output
PA12.GPIO_Label=OC_COMP_INT2
PA12.GPIO_PuPd=GPIO_PULLDOWN
PA12.Signal=GPIO_Input
PA15.GPIO_Label=RS485_DE
PA15.Signal=GPIO_Output
PA3.GPIO_Label=M1_CURR_AMPL_U
PA3.Mode=IN3
PA3.Signal=ADC_IN3
PA4.GPIO_Label=M1_CURR_AMPL_V
PA4.Mode=IN4
PA4.Signal=ADC_IN4
PA5.GPIO_Label=M1_CURR_AMPL_W
PA5.Mode=IN5
PA5.Signal=ADC_IN5
PA6.GPIO_Label=M1_ENCODER_A
PA6.Signal=S_TIM3_CH1
PA7.GPIO_Label=M1_ENCODER_B
PA7.Signal=S_TIM3_CH2
PA8.GPIO_Label=M1_PWM_UH
PA8.GPIO_PuPd=GPIO_PULLDOWN
PA8.GPIO_Speed=GPIO_SPEED_FREQ_HIGH
PA8.Signal=S_TIM1_CH1
PA9.GPIO_Label=M1_PWM_VH
PA9.GPIO_PuPd=GPIO_PULLDOWN
PA9.GPIO_Speed=GPIO_SPEED_FREQ_HIGH
PA9.Signal=S_TIM1_CH2
PB1.GPIO_Label=M1_BUS_VOLTAGE
PB1.Mode=IN9
PB1.Signal=ADC_IN9
PB12.GPIO_Label=M1_OCP
PB12.GPIO_PuPd=GPIO_PULLDOWN
PB12.Mode=Activate-Break-Input
PB12.Signal=TIM1_BKIN
PB13.GPIO_Label=M1_PWM_UL
PB13.GPIO_PuPd=GPIO_PULLDOWN
PB13.GPIO_Speed=GPIO_SPEED_FREQ_HIGH
PB13.Mode=PWM Generation1 CH1 CH1N
PB13.Signal=TIM1_CH1N
PB14.GPIO_Label=M1_PWM_VL
PB14.GPIO_PuPd=GPIO_PULLDOWN
PB14.GPIO_Speed=GPIO_SPEED_FREQ_HIGH
PB14.Mode=PWM Generation2 CH2 CH2N
PB14.Signal=TIM1_CH2N
PB15.GPIO_Label=M1_PWM_WL
PB15.GPIO_PuPd=GPIO_PULLDOWN
PB15.GPIO_Speed=GPIO_SPEED_FREQ_HIGH
PB15.Mode=PWM Generation3 CH3 CH3N
PB15.Signal=TIM1_CH3N
PB6.Mode=Asynchronous
PB6.Signal=USART1_TX
PB7.Mode=Asynchronous
PB7.Signal=USART1_RX
PF0-OSC_IN.GPIO_Label=LED
PF0-OSC_IN.Signal=GPIO_Output
PF1-OSC_OUT.GPIO_Label=M1_ENCODER_Z
PF1-OSC_OUT.Signal=GPXTI1
PF6.GPIO_Label=OCTH_STBY2
PF6.GPIO_PuPd=GPIO_PULLDOWN
PF6.PinState=GPIO_PIN_SET
PF6.Signal=GPIO_Output
PF7.GPIO_Label=OCTH_STBY1
PF7.GPIO_PuPd=GPIO_PULLDOWN
PF7.PinState=GPIO_PIN_SET
PF7.Signal=GPIO_Output
ProjectManager.HeapSize=0x80
ProjectManager.StackSize=0x400
ProjectManager.TargetToolchain=STM32CubeIDE
RCC.AHBFreq_Value=48000000
RCC.APB1Freq_Value=48000000
RCC.APB1TimFreq_Value=48000000
RCC.EnbaleCSS=true
RCC.HCLKFreq_Value=48000000
RCC.PLLMUL=RCC_PLL_MUL12
RCC.SYSCLKFreq_VALUE=48000000
RCC.SYSCLKSource=RCC_SYSCLKSOURCE_PLLCLK
SH.S_TIM1_CH1.0=TIM1_CH1,PWM Generation1 CH1 CH1N
SH.S_TIM1_CH2.0=TIM1_CH2,PWM Generation2 CH2 CH2N
SH.S_TIM1_CH3.0=TIM1_CH3,PWM Generation3 CH3 CH3N
SH.S_TIM3_CH1.0=TIM3_CH1,Encoder_Interface
SH.S_TIM3_CH2.0=TIM3_CH2,Encoder_Interface
TIM1.AutoReloadPreload=TIM_AUTORELOAD_PRELOAD_DISABLE
TIM1.AutomaticOutput=TIM_AUTOMATICOUTPUT_DISABLE
TIM1.BreakPolarity=TIM_BREAKPOLARITY_HIGH
TIM1.BreakState=TIM_BREAK_ENABLE
TIM1.Channel-PWM\ Generation1\ CH1\ CH1N=TIM_CHANNEL_1
TIM1.Channel-PWM\ Generation2\ CH2\ CH2N=TIM_CHANNEL_2
TIM1.Channel-PWM\ Generation3\ CH3\ CH3N=TIM_CHANNEL_3
TIM1.Channel-PWM\ Generation4\ No\ Output=TIM_CHANNEL_4
TIM1.ClockDivision=TIM_CLOCKDIVISION_DIV2
TIM1.CounterMode=TIM_COUNTERMODE_CENTERALIGNED1
TIM1.DeadTime=((DEAD_TIME_COUNTS) / 2)
TIM1.LockLevel=TIM_LOCKLEVEL_1
TIM1.OCIdleState_1=TIM_OCIDLESTATE_RESET
TIM1.OCIdleState_2=TIM_OCIDLESTATE_RESET
TIM1.OCIdleState_3=TIM_OCIDLESTATE_RESET
TIM1.OCIdleState_4=TIM_OCIDLESTATE_RESET
TIM1.OCMode_PWM-PWM\ Generation1\ CH1\ CH1N=TIM_OCMODE_PWM1
TIM1.OCMode_PWM-PWM\ Generation2\ CH2\ CH2N=TIM_OCMODE_PWM1
TIM1.OCMode_PWM-PWM\ Generation3\ CH3\ CH3N=TIM_OCMODE_PWM1
TIM1.OCMode_PWM-PWM\ Generation4\ No\ Output=TIM_OCMODE_PWM2
TIM1.OCNIdleState_1=TIM_OCNIDLESTATE_RESET
TIM1.OCNIdleState_2=TIM_OCNIDLESTATE_RESET
TIM1.OCNIdleState_3=TIM_OCNIDLESTATE_RESET
TIM1.OCNPolarity_1=TIM_OCNPOLARITY_HIGH
TIM1.OCNPolarity_2=TIM_OCNPOLARITY_HIGH
TIM1.OCNPolarity_3=TIM_OCNPOLARITY_HIGH
TIM1.OCPolarity_1=TIM_OCPOLARITY_HIGH
TIM1.OCPolarity_2=TIM_OCPOLARITY_HIGH
TIM1.OCPolarity_3=TIM_OCPOLARITY_HIGH
TIM1.OCPolarity_4=TIM_OCPOLARITY_HIGH
TIM1.OffStateIDLEMode=TIM_OSSI_ENABLE
TIM1.OffStateRunMode=TIM_OSSR_ENABLE
TIM1.Period=((PWM_PERIOD_CYCLES) / 2)
TIM1.Prescaler=((TIM_CLOCK_DIVIDER) - 1)
TIM1.Pulse-PWM\ Generation1\ CH1=((PWM_PERIOD_CYCLES) / 4)
TIM1.Pulse-PWM\ Generation2\ CH2=((PWM_PERIOD_CYCLES) / 4)
TIM1.Pulse-PWM\ Generation3\ CH3=((PWM_PERIOD_CYCLES) / 4)
TIM1.Pulse-PWM\ Generation4\ No\ Output=(((PWM_PERIOD_CYCLES) / 2) - (HTMIN))
TIM1.RepetitionCounter=(REP_COUNTER)
TIM1.TIM_MasterOutputTrigger=TIM_TRGO_OC4REF
TIM1.TIM_MasterSlaveMode=TIM_MASTERSLAVEMODE_DISABLE
TIM14.Channel=TIM_CHANNEL_1
TIM14.Prescaler=2399
TIM16.Channel=TIM_CHANNEL_1
TIM16.Period=1999
TIM16.Prescaler=47
TIM3.EncoderMode=TIM_ENCODERMODE_TI12
TIM3.IC1Filter=M1_ENC_IC_FILTER
TIM3.IC1Polarity=TIM_ICPOLARITY_RISING
TIM3.IC2Filter=M1_ENC_IC_FILTER
TIM3.IC2Polarity=TIM_ICPOLARITY_RISING
TIM3.Period=M1_PULSE_NBR
USART1.BaudRate=19200
USART1.VirtualMode-Asynchronous=VM_ASYNC
VP_MotorControl_MC_ENABLED.Mode=Enabled
VP_TIM14_VS_ClockSourceINT.Mode=Enable_Timer
VP_TIM14_VS_no_output1.Mode=PWM Generation1 No Output
VP_TIM16_VS_ClockSourceINT.Mode=Enable_Timer
VP_TIM16_VS_no_output1.Mode=PWM Generation1 No Output
VP_TIM1_VS_no_output4.Mode=PWM Generation4 No Output
board=custom

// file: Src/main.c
/* USER CODE BEGIN Header */
/**
 ******************************************************************************
 * @file           : main.c
 * @brief          : Main program body for motor control application
 * @attention      : Copyright (c) 2020 STMicroelectronics. All rights reserved.
 *                  Licensed under Ultimate Liberty license SLA0044.
 *                  Obtain a copy of the License at: www.st.com/SLA0044
 ******************************************************************************
 */
/* USER CODE END Header */

#include "main.h"
#include "motorcontrol.h"
#include "Command_APIs.h"

/* USER CODE BEGIN Includes */
#include "mc_api.h" // Motor control API for interacting with motor functions
/* USER CODE END Includes */

/* USER CODE BEGIN PV */
float fTargetPos = 0;               // Target position for motor movement (radians)
float movementDuration_s = 2;       // Duration of motor movement in seconds
int32_t targetDeg = 0;              // Target position in degrees
uint8_t RecvdCommand[11];           // Buffer for received command data
uint8_t counterBytesCommand = 0;    // Counter for received command bytes
comState_t comState = IDEL;         // Current communication state
float Postion;                      // Target position from received message
float DurationPosition;             // Duration for position command
float curPosition;                  // Current motor position
int16_t Speed;                      // Motor speed for speed control
int16_t Torque;                     // Motor torque for torque control
uint16_t Time;                      // Time duration for speed/torque commands
uint8_t contMode;                   // Current control mode of the motor
uint8_t FirstBytesSentMSG[4];       // First 4 bytes of message to send
uint8_t SecondBytesSentMSG[4];      // Second 4 bytes of message to send
uint8_t ReceivedMessage[11];        // Buffer for received message
uint8_t isReceivedMEG = 0;          // Flag indicating a message was received
uint8_t FirstBytesRevdMSG[4];       // First 4 bytes of received message
uint8_t SecondBytesRevdMSG[4];      // Second 4 bytes of received message
uint8_t alignmentStatus = 0;        // Status of motor encoder alignment
uint8_t retries = 0;                // Retry counter for motor alignment
const uint8_t maxRetries = 5;       // Maximum number of retries for alignment
extern int messageCounter;           // Counter for processed messages

/* USER CODE END PV */

void SystemClock_Config(void);      // Configure system clock
static void MX_GPIO_Init(void);     // Initialize GPIO pins
static void MX_DMA_Init(void);      // Initialize DMA controller
static void MX_ADC_Init(void);      // Initialize ADC peripheral
static void MX_TIM1_Init(void);     // Initialize TIM1 for PWM generation
static void MX_TIM3_Init(void);     // Initialize TIM3 for encoder interface
static void MX_TIM14_Init(void);    // Initialize TIM14 for auxiliary timing
static void MX_TIM16_Init(void);    // Initialize TIM16 for auxiliary PWM
static void MX_USART1_UART_Init(void); // Initialize USART1 for communication
static void MX_NVIC_Init(void);     // Initialize NVIC for interrupts
/* USER CODE BEGIN PFP */
bool isMovementComplete(void);       // Check if motor movement is complete
uint8_t ProcessReceivedMessage(uint8_t *message); // Process incoming messages
/* USER CODE END PFP */

/* USER CODE BEGIN 0 */
/**
 * @brief  Checks if the motor movement is complete
 * @retval bool - Returns true if movement is complete, false otherwise
 */
bool isMovementComplete(void) {
    return (MC_GetControlPositionStatusMotor1() == TC_READY_FOR_COMMAND);
}

/**
 * @brief  Processes received message and updates motor control parameters
 * @param  message: Pointer to the received message buffer
 * @retval uint8_t - Returns 0 on success
 */
uint8_t ProcessReceivedMessage(uint8_t *message) {
	// Extract first and second 4 bytes from the message
	FirstBytesRevdMSG[0] = message[3];
	FirstBytesRevdMSG[1] = message[4];
	FirstBytesRevdMSG[2] = message[5];
	FirstBytesRevdMSG[3] = message[6];
	SecondBytesRevdMSG[0] = message[7];
	SecondBytesRevdMSG[1] = message[8];
	SecondBytesRevdMSG[2] = message[9];
	SecondBytesRevdMSG[3] = message[10];

	// Validate message header (0x48, 0x5A)
	if (message[0] == 72 && message[1] == 90) {
		switch (message[2]) {
		case STOP_MOTOR:
			messageCounter--; // Decrement counter (purpose unclear)

			comState = STOP_MOTOR; // Set state to stop motor
			break;
		case SET_POSITION:
			messageCounter--; // Decrement counter (purpose unclear)

			MC_StartMotor1(); // Start motor
			ProcessReceivedFloat(FirstBytesRevdMSG, &Postion); // Extract position
			ProcessReceivedFloat(SecondBytesRevdMSG, &DurationPosition); // Extract duration
			comState = SET_POSITION; // Set state to position control
			break;
		case SET_SPEED:
			messageCounter--; // Decrement counter (purpose unclear)
			MC_StartMotor1(); // Start motor
			ProcessReceivedUint16(FirstBytesRevdMSG, &Time); // Extract time
			ProcessReceivedInt16(SecondBytesRevdMSG, &Speed); // Extract speed
			comState = SET_SPEED; // Set state to speed control
			break;
		case SET_TORQUE:
			messageCounter--; // Decrement counter (purpose unclear)

			MC_StartMotor1(); // Start motor
			ProcessReceivedUint16(FirstBytesRevdMSG, &Time); // Extract time
			ProcessReceivedInt16(SecondBytesRevdMSG, &Torque); // Extract torque
			comState = SET_TORQUE; // Set state to torque control
			break;
		case GET_POSITION:
			messageCounter--; // Decrement counter (purpose unclear)

			comState = GET_POSITION; // Set state to get position
			break;
		case GET_CONTROL_MODE:
			messageCounter--; // Decrement counter (purpose unclear)

			comState = GET_CONTROL_MODE; // Set state to get control mode
			break;
		default:
			break; // Ignore invalid commands
		}
	}
	return 0; // Success
}
/* USER CODE END 0 */

/**
 * @brief  Main application entry point
 * @retval int
 */
int main(void) {

    /* MCU Configuration--------------------------------------------------------*/
    HAL_Init(); // Initialize HAL library

    /* Configure system clock */
    SystemClock_Config();

    /* Initialize peripherals */
    MX_GPIO_Init();
    MX_DMA_Init();
    MX_ADC_Init();
    MX_TIM1_Init();
    MX_TIM3_Init();
    MX_MotorControl_Init();
    MX_TIM14_Init();
    MX_TIM16_Init();
    MX_USART1_UART_Init();
    MX_NVIC_Init();

    /* USER CODE BEGIN 2 */
    LL_TIM_EnableIT_UPDATE(TIM16); // Enable TIM16 update interrupt
    LL_TIM_EnableCounter(TIM16);   // Start TIM16 counter
    LL_USART_EnableIT_RXNE(USART1); // Enable USART1 RX not empty interrupt
    LL_GPIO_SetOutputPin(LED_GPIO_Port, LED_Pin); // Turn on LED
    MC_StartMotor1(); // Start motor 1

    // Wait for encoder alignment
    while (MC_GetAlignmentStatusMotor1() != TC_ALIGNMENT_COMPLETED) {
        if (MC_GetOccurredFaultsMotor1() != 0) {
            MC_AcknowledgeFaultMotor1(); // Clear fault
            LL_GPIO_ResetOutputPin(LED_GPIO_Port, LED_Pin); // Turn off LED
            HAL_Delay(500); // Delay 500ms
            MC_StartMotor1(); // Restart motor
            LL_GPIO_SetOutputPin(LED_GPIO_Port, LED_Pin); // Turn on LED
            HAL_Delay(500); // Delay 500ms
        }
    }

    HAL_Delay(100); // Short delay after alignment
    LL_GPIO_ResetOutputPin(LED_GPIO_Port, LED_Pin); // Turn off LED
    comState = IDEL; // Set initial communication state to idle
    /* USER CODE END 2 */

    /* Main loop */
    while (1) {
        // Blink LED if counter messageCounter >= 5
        if (messageCounter >= 5) {
            LL_GPIO_SetOutputPin(LED_GPIO_Port, LED_Pin); // Turn on LED
            HAL_Delay(200); // Delay 200ms
            LL_GPIO_ResetOutputPin(LED_GPIO_Port, LED_Pin); // Turn off LED
            HAL_Delay(200); // Delay 200ms
        }

        /* USER CODE BEGIN 3 */
        // Handle motor faults
        if (MC_GetOccurredFaultsMotor1() != 0) {
            LL_GPIO_SetOutputPin(LED_GPIO_Port, LED_Pin); // Turn on LED
            MC_AcknowledgeFaultMotor1(); // Clear fault
            comState = IDEL; // Reset to idle state
        } else {
            LL_GPIO_ResetOutputPin(LED_GPIO_Port, LED_Pin); // Turn off LED
        }

        // Process communication state
        switch (comState) {
            case STOP_MOTOR:
                MC_StopMotor1(); // Stop motor
                break;
            case SET_POSITION:
                MC_ProgramPositionCommandMotor1(Postion, DurationPosition); // Set position
                break;
            case SET_SPEED:
                MC_ProgramSpeedRampMotor1(Speed, Time); // Set speed
                break;
            case SET_TORQUE:
                MC_ProgramTorqueRampMotor1(Torque, Time); // Set torque
                break;
            case GET_POSITION:
                curPosition = MC_GetCurrentPosition1(); // Get current position
                ConvertFloatTwoBytes(curPosition, FirstBytesSentMSG); // Convert to bytes
                SendMessage(GET_POSITION, FirstBytesSentMSG, FirstBytesSentMSG); // Send position
                comState = IDEL; // Reset to idle
                break;
            case GET_CONTROL_MODE:
                contMode = MC_GetControlModeMotor1(); // Get control mode
                FirstBytesSentMSG[0] = contMode; // Store mode
                SendMessage(GET_CONTROL_MODE, FirstBytesSentMSG, FirstBytesSentMSG); // Send mode
                comState = IDEL; // Reset to idle
                break;
        }
        /* USER CODE END 3 */
    }
}

/**
 * @brief  Configures the system clock to 48 MHz using PLL with HSI as source
 * @retval None
 */
void SystemClock_Config(void) {
    LL_FLASH_SetLatency(LL_FLASH_LATENCY_1); // Set flash latency
    if (LL_FLASH_GetLatency() != LL_FLASH_LATENCY_1) {
        Error_Handler(); // Handle latency error
    }

    LL_RCC_HSI_Enable(); // Enable HSI oscillator
    while (LL_RCC_HSI_IsReady() != 1); // Wait for HSI ready
    LL_RCC_HSI_SetCalibTrimming(16); // Set HSI calibration
    LL_RCC_HSI14_Enable(); // Enable HSI14 for ADC
    while (LL_RCC_HSI14_IsReady() != 1); // Wait for HSI14 ready
    LL_RCC_HSI14_SetCalibTrimming(16); // Set HSI14 calibration

    // Configure PLL: HSI/2 * 12 = 48 MHz
    LL_RCC_PLL_ConfigDomain_SYS(LL_RCC_PLLSOURCE_HSI_DIV_2, LL_RCC_PLL_MUL_12);
    LL_RCC_PLL_Enable(); // Enable PLL
    while (LL_RCC_PLL_IsReady() != 1); // Wait for PLL ready

    LL_RCC_SetAHBPrescaler(LL_RCC_SYSCLK_DIV_1); // Set AHB prescaler
    LL_RCC_SetAPB1Prescaler(LL_RCC_APB1_DIV_1); // Set APB1 prescaler
    LL_RCC_SetSysClkSource(LL_RCC_SYS_CLKSOURCE_PLL); // Set PLL as system clock
    while (LL_RCC_GetSysClkSource() != LL_RCC_SYS_CLKSOURCE_STATUS_PLL); // Wait for system clock switch

    LL_SetSystemCoreClock(48000000); // Set core clock to 48 MHz
    if (HAL_InitTick(TICK_INT_PRIORITY) != HAL_OK) { // Update time base
        Error_Handler(); // Handle tick init error
    }

    LL_RCC_HSI14_EnableADCControl(); // Enable HSI14 for ADC
    LL_RCC_SetUSARTClockSource(LL_RCC_USART1_CLKSOURCE_PCLK1); // Set USART1 clock source
}

/**
 * @brief  Configures NVIC interrupts for peripherals
 * @retval None
 */
static void MX_NVIC_Init(void) {
    NVIC_SetPriority(TIM1_BRK_UP_TRG_COM_IRQn, 0); // TIM1 interrupt priority
    NVIC_EnableIRQ(TIM1_BRK_UP_TRG_COM_IRQn); // Enable TIM1 interrupt
    NVIC_SetPriority(DMA1_Channel1_IRQn, 1); // DMA1 channel 1 priority
    NVIC_EnableIRQ(DMA1_Channel1_IRQn); // Enable DMA1 channel 1 interrupt
    NVIC_SetPriority(TIM3_IRQn, 3); // TIM3 interrupt priority
    NVIC_EnableIRQ(TIM3_IRQn); // Enable TIM3 interrupt
    NVIC_SetPriority(EXTI0_1_IRQn, 3); // EXTI0_1 interrupt priority
    NVIC_EnableIRQ(EXTI0_1_IRQn); // Enable EXTI0_1 interrupt
    NVIC_SetPriority(TIM14_IRQn, 2); // TIM14 interrupt priority
    NVIC_EnableIRQ(TIM14_IRQn); // Enable TIM14 interrupt
    NVIC_SetPriority(TIM16_IRQn, 2); // TIM16 interrupt priority
    NVIC_EnableIRQ(TIM16_IRQn); // Enable TIM16 interrupt
    NVIC_SetPriority(USART1_IRQn, 3); // USART1 interrupt priority
    NVIC_EnableIRQ(USART1_IRQn); // Enable USART1 interrupt
}

/**
 * @brief  Initializes ADC for motor current and voltage sensing
 * @retval None
 */
static void MX_ADC_Init(void) {
    LL_ADC_InitTypeDef ADC_InitStruct = {0}; // ADC initialization structure
    LL_ADC_REG_InitTypeDef ADC_REG_InitStruct = {0}; // ADC regular channel structure
    LL_GPIO_InitTypeDef GPIO_InitStruct = {0}; // GPIO initialization structure

    LL_APB1_GRP2_EnableClock(LL_APB1_GRP2_PERIPH_ADC1); // Enable ADC1 clock
    LL_AHB1_GRP1_EnableClock(LL_AHB1_GRP1_PERIPH_GPIOA); // Enable GPIOA clock
    LL_AHB1_GRP1_EnableClock(LL_AHB1_GRP1_PERIPH_GPIOB); // Enable GPIOB clock

    // Configure GPIO pins for ADC (PA3, PA4, PA5, PB1)
    GPIO_InitStruct.Pin = M1_CURR_AMPL_U_Pin;
    GPIO_InitStruct.Mode = LL_GPIO_MODE_ANALOG;
    GPIO_InitStruct.Pull = LL_GPIO_PULL_NO;
    LL_GPIO_Init(M1_CURR_AMPL_U_GPIO_Port, &GPIO_InitStruct);

    GPIO_InitStruct.Pin = M1_CURR_AMPL_V_Pin;
    LL_GPIO_Init(M1_CURR_AMPL_V_GPIO_Port, &GPIO_InitStruct);

    GPIO_InitStruct.Pin = M1_CURR_AMPL_W_Pin;
    LL_GPIO_Init(M1_CURR_AMPL_W_GPIO_Port, &GPIO_InitStruct);

    GPIO_InitStruct.Pin = M1_BUS_VOLTAGE_Pin;
    LL_GPIO_Init(M1_BUS_VOLTAGE_GPIO_Port, &GPIO_InitStruct);

    // Configure DMA for ADC
    LL_DMA_SetDataTransferDirection(DMA1, LL_DMA_CHANNEL_1, LL_DMA_DIRECTION_PERIPH_TO_MEMORY);
    LL_DMA_SetChannelPriorityLevel(DMA1, LL_DMA_CHANNEL_1, LL_DMA_PRIORITY_HIGH);
    LL_DMA_SetMode(DMA1, LL_DMA_CHANNEL_1, LL_DMA_MODE_CIRCULAR);
    LL_DMA_SetPeriphIncMode(DMA1, LL_DMA_CHANNEL_1, LL_DMA_PERIPH_NOINCREMENT);
    LL_DMA_SetMemoryIncMode(DMA1, LL_DMA_CHANNEL_1, LL_DMA_MEMORY_INCREMENT);
    LL_DMA_SetPeriphSize(DMA1, LL_DMA_CHANNEL_1, LL_DMA_PDATAALIGN_HALFWORD);
    LL_DMA_SetMemorySize(DMA1, LL_DMA_CHANNEL_1, LL_DMA_MDATAALIGN_HALFWORD);

    // Configure ADC channels (3, 4, 5, 9)
    LL_ADC_REG_SetSequencerChAdd(ADC1, LL_ADC_CHANNEL_3);
    LL_ADC_REG_SetSequencerChAdd(ADC1, LL_ADC_CHANNEL_4);
    LL_ADC_REG_SetSequencerChAdd(ADC1, LL_ADC_CHANNEL_5);
    LL_ADC_REG_SetSequencerChAdd(ADC1, LL_ADC_CHANNEL_9);

    // Configure ADC global features
    ADC_InitStruct.Clock = LL_ADC_CLOCK_ASYNC;
    ADC_InitStruct.Resolution = LL_ADC_RESOLUTION_12B;
    ADC_InitStruct.DataAlignment = LL_ADC_DATA_ALIGN_LEFT;
    ADC_InitStruct.LowPowerMode = LL_ADC_LP_MODE_NONE;
    LL_ADC_Init(ADC1, &ADC_InitStruct);

    ADC_REG_InitStruct.TriggerSource = LL_ADC_REG_TRIG_EXT_TIM1_TRGO;
    ADC_REG_InitStruct.SequencerDiscont = LL_ADC_REG_SEQ_DISCONT_DISABLE;
    ADC_REG_InitStruct.ContinuousMode = LL_ADC_REG_CONV_SINGLE;
    ADC_REG_InitStruct.DMATransfer = LL_ADC_REG_DMA_TRANSFER_UNLIMITED;
    ADC_REG_InitStruct.Overrun = LL_ADC_REG_OVR_DATA_PRESERVED;
    LL_ADC_REG_Init(ADC1, &ADC_REG_InitStruct);

    LL_ADC_REG_SetSequencerScanDirection(ADC1, LL_ADC_REG_SEQ_SCAN_DIR_FORWARD);
    LL_ADC_SetSamplingTimeCommonChannels(ADC1, LL_ADC_SAMPLINGTIME_7CYCLES_5);
    LL_ADC_DisableIT_EOC(ADC1); // Disable end of conversion interrupt
    LL_ADC_DisableIT_EOS(ADC1); // Disable end of sequence interrupt
    LL_ADC_REG_SetTriggerEdge(ADC1, LL_ADC_REG_TRIG_EXT_RISING);
}

/**
 * @brief  Initializes TIM1 for PWM generation for motor control
 * @retval None
 */
static void MX_TIM1_Init(void) {
    LL_TIM_InitTypeDef TIM_InitStruct = {0}; // TIM1 initialization structure
    LL_TIM_OC_InitTypeDef TIM_OC_InitStruct = {0}; // Output compare structure
    LL_TIM_BDTR_InitTypeDef TIM_BDTRInitStruct = {0}; // Break and dead-time structure
    LL_GPIO_InitTypeDef GPIO_InitStruct = {0}; // GPIO initialization structure

    LL_APB1_GRP2_EnableClock(LL_APB1_GRP2_PERIPH_TIM1); // Enable TIM1 clock
    LL_AHB1_GRP1_EnableClock(LL_AHB1_GRP1_PERIPH_GPIOB); // Enable GPIOB clock
    LL_AHB1_GRP1_EnableClock(LL_AHB1_GRP1_PERIPH_GPIOA); // Enable GPIOA clock

    // Configure GPIO pin for TIM1 break input (PB12)
    GPIO_InitStruct.Pin = M1_OCP_Pin;
    GPIO_InitStruct.Mode = LL_GPIO_MODE_ALTERNATE;
    GPIO_InitStruct.Speed = LL_GPIO_SPEED_FREQ_LOW;
    GPIO_InitStruct.OutputType = LL_GPIO_OUTPUT_PUSHPULL;
    GPIO_InitStruct.Pull = LL_GPIO_PULL_DOWN;
    GPIO_InitStruct.Alternate = LL_GPIO_AF_2;
    LL_GPIO_Init(M1_OCP_GPIO_Port, &GPIO_InitStruct);

    // Configure TIM1 channels for PWM
    TIM_InitStruct.Prescaler = ((TIM_CLOCK_DIVIDER) - 1);
    TIM_InitStruct.CounterMode = LL_TIM_COUNTERMODE_CENTER_UP;
    TIM_InitStruct.Autoreload = ((PWM_PERIOD_CYCLES) / 2);
    TIM_InitStruct.ClockDivision = LL_TIM_CLOCKDIVISION_DIV2;
    TIM_InitStruct.RepetitionCounter = (REP_COUNTER);
    LL_TIM_Init(TIM1, &TIM_InitStruct);
    LL_TIM_DisableARRPreload(TIM1);

    // Configure PWM channels (CH1, CH2, CH3, CH4)
    LL_TIM_OC_EnablePreload(TIM1, LL_TIM_CHANNEL_CH1);
    TIM_OC_InitStruct.OCMode = LL_TIM_OCMODE_PWM1;
    TIM_OC_InitStruct.OCState = LL_TIM_OCSTATE_DISABLE;
    TIM_OC_InitStruct.OCNState = LL_TIM_OCSTATE_DISABLE;
    TIM_OC_InitStruct.CompareValue = 0;
    TIM_OC_InitStruct.OCPolarity = LL_TIM_OCPOLARITY_HIGH;
    TIM_OC_InitStruct.OCNPolarity = LL_TIM_OCPOLARITY_HIGH;
    TIM_OC_InitStruct.OCIdleState = LL_TIM_OCIDLESTATE_LOW;
    TIM_OC_InitStruct.OCNIdleState = LL_TIM_OCIDLESTATE_LOW;
    LL_TIM_OC_Init(TIM1, LL_TIM_CHANNEL_CH1, &TIM_OC_InitStruct);
    LL_TIM_OC_DisableFast(TIM1, LL_TIM_CHANNEL_CH1);

    LL_TIM_OC_EnablePreload(TIM1, LL_TIM_CHANNEL_CH2);
    LL_TIM_OC_Init(TIM1, LL_TIM_CHANNEL_CH2, &TIM_OC_InitStruct);
    LL_TIM_OC_DisableFast(TIM1, LL_TIM_CHANNEL_CH2);

    LL_TIM_OC_EnablePreload(TIM1, LL_TIM_CHANNEL_CH3);
    LL_TIM_OC_Init(TIM1, LL_TIM_CHANNEL_CH3, &TIM_OC_InitStruct);
    LL_TIM_OC_DisableFast(TIM1, LL_TIM_CHANNEL_CH3);

    LL_TIM_OC_EnablePreload(TIM1, LL_TIM_CHANNEL_CH4);
    TIM_OC_InitStruct.OCMode = LL_TIM_OCMODE_PWM2;
    TIM_OC_InitStruct.CompareValue = (((PWM_PERIOD_CYCLES) / 2) - (HTMIN));
    LL_TIM_OC_Init(TIM1, LL_TIM_CHANNEL_CH4, &TIM_OC_InitStruct);
    LL_TIM_OC_DisableFast(TIM1, LL_TIM_CHANNEL_CH4);

    LL_TIM_SetTriggerOutput(TIM1, LL_TIM_TRGO_OC4REF); // Set trigger output
    LL_TIM_DisableMasterSlaveMode(TIM1);

    // Configure break and dead-time
    TIM_BDTRInitStruct.OSSRState = LL_TIM_OSSR_ENABLE;
    TIM_BDTRInitStruct.OSSIState = LL_TIM_OSSI_ENABLE;
    TIM_BDTRInitStruct.LockLevel = LL_TIM_LOCKLEVEL_1;
    TIM_BDTRInitStruct.DeadTime = ((DEAD_TIME_COUNTS) / 2);
    TIM_BDTRInitStruct.BreakState = LL_TIM_BREAK_ENABLE;
    TIM_BDTRInitStruct.BreakPolarity = LL_TIM_BREAK_POLARITY_HIGH;
    TIM_BDTRInitStruct.AutomaticOutput = LL_TIM_AUTOMATICOUTPUT_DISABLE;
    LL_TIM_BDTR_Init(TIM1, &TIM_BDTRInitStruct);

    // Configure GPIO pins for PWM outputs
    GPIO_InitStruct.Pin = M1_PWM_UL_Pin;
    GPIO_InitStruct.Mode = LL_GPIO_MODE_ALTERNATE;
    GPIO_InitStruct.Speed = LL_GPIO_SPEED_FREQ_HIGH;
    GPIO_InitStruct.OutputType = LL_GPIO_OUTPUT_PUSHPULL;
    GPIO_InitStruct.Pull = LL_GPIO_PULL_DOWN;
    GPIO_InitStruct.Alternate = LL_GPIO_AF_2;
    LL_GPIO_Init(M1_PWM_UL_GPIO_Port, &GPIO_InitStruct);

    GPIO_InitStruct.Pin = M1_PWM_VL_Pin;
    LL_GPIO_Init(M1_PWM_VL_GPIO_Port, &GPIO_InitStruct);

    GPIO_InitStruct.Pin = M1_PWM_WL_Pin;
    LL_GPIO_Init(M1_PWM_WL_GPIO_Port, &GPIO_InitStruct);

    GPIO_InitStruct.Pin = M1_PWM_UH_Pin;
    LL_GPIO_Init(M1_PWM_UH_GPIO_Port, &GPIO_InitStruct);

    GPIO_InitStruct.Pin = M1_PWM_VH_Pin;
    LL_GPIO_Init(M1_PWM_VH_GPIO_Port, &GPIO_InitStruct);

    GPIO_InitStruct.Pin = M1_PWM_WH_Pin;
    LL_GPIO_Init(M1_PWM_WH_GPIO_Port, &GPIO_InitStruct);
}

/**
 * @brief  Initializes TIM3 for encoder interface
 * @retval None
 */
static void MX_TIM3_Init(void) {
    LL_TIM_InitTypeDef TIM_InitStruct = {0}; // TIM3 initialization structure
    LL_GPIO_InitTypeDef GPIO_InitStruct = {0}; // GPIO initialization structure

    LL_APB1_GRP1_EnableClock(LL_APB1_GRP1_PERIPH_TIM3); // Enable TIM3 clock
    LL_AHB1_GRP1_EnableClock(LL_AHB1_GRP1_PERIPH_GPIOA); // Enable GPIOA clock

    // Configure GPIO pins for encoder (PA6, PA7)
    GPIO_InitStruct.Pin = M1_ENCODER_A_Pin;
    GPIO_InitStruct.Mode = LL_GPIO_MODE_ALTERNATE;
    GPIO_InitStruct.Speed = LL_GPIO_SPEED_FREQ_LOW;
    GPIO_InitStruct.OutputType = LL_GPIO_OUTPUT_PUSHPULL;
    GPIO_InitStruct.Pull = LL_GPIO_PULL_NO;
    GPIO_InitStruct.Alternate = LL_GPIO_AF_1;
    LL_GPIO_Init(M1_ENCODER_A_GPIO_Port, &GPIO_InitStruct);

    GPIO_InitStruct.Pin = M1_ENCODER_B_Pin;
    LL_GPIO_Init(M1_ENCODER_B_GPIO_Port, &GPIO_InitStruct);

    // Configure TIM3 for encoder mode
    LL_TIM_SetEncoderMode(TIM3, LL_TIM_ENCODERMODE_X4_TI12);
    LL_TIM_IC_SetActiveInput(TIM3, LL_TIM_CHANNEL_CH1, LL_TIM_ACTIVEINPUT_DIRECTTI);
    LL_TIM_IC_SetPrescaler(TIM3, LL_TIM_CHANNEL_CH1, LL_TIM_ICPSC_DIV1);
    LL_TIM_IC_SetFilter(TIM3, LL_TIM_CHANNEL_CH1, M1_ENC_IC_FILTER);
    LL_TIM_IC_SetPolarity(TIM3, LL_TIM_CHANNEL_CH1, LL_TIM_IC_POLARITY_RISING);
    LL_TIM_IC_SetActiveInput(TIM3, LL_TIM_CHANNEL_CH2, LL_TIM_ACTIVEINPUT_DIRECTTI);
    LL_TIM_IC_SetPrescaler(TIM3, LL_TIM_CHANNEL_CH2, LL_TIM_ICPSC_DIV1);
    LL_TIM_IC_SetFilter(TIM3, LL_TIM_CHANNEL_CH2, M1_ENC_IC_FILTER);
    LL_TIM_IC_SetPolarity(TIM3, LL_TIM_CHANNEL_CH2, LL_TIM_IC_POLARITY_RISING);

    TIM_InitStruct.Prescaler = 0;
    TIM_InitStruct.CounterMode = LL_TIM_COUNTERMODE_UP;
    TIM_InitStruct.Autoreload = M1_PULSE_NBR;
    TIM_InitStruct.ClockDivision = LL_TIM_CLOCKDIVISION_DIV1;
    LL_TIM_Init(TIM3, &TIM_InitStruct);
    LL_TIM_DisableARRPreload(TIM3);
    LL_TIM_SetTriggerOutput(TIM3, LL_TIM_TRGO_RESET);
    LL_TIM_DisableMasterSlaveMode(TIM3);
}

/**
 * @brief  Initializes TIM14 for auxiliary timing
 * @retval None
 */
static void MX_TIM14_Init(void) {
    LL_TIM_InitTypeDef TIM_InitStruct = {0}; // TIM14 initialization structure
    LL_TIM_OC_InitTypeDef TIM_OC_InitStruct = {0}; // Output compare structure

    LL_APB1_GRP1_EnableClock(LL_APB1_GRP1_PERIPH_TIM14); // Enable TIM14 clock

    // Configure TIM14 for PWM
    TIM_InitStruct.Prescaler = 2399;
    TIM_InitStruct.CounterMode = LL_TIM_COUNTERMODE_UP;
    TIM_InitStruct.Autoreload = 0;
    TIM_InitStruct.ClockDivision = LL_TIM_CLOCKDIVISION_DIV1;
    LL_TIM_Init(TIM14, &TIM_InitStruct);
    LL_TIM_DisableARRPreload(TIM14);

    LL_TIM_OC_EnablePreload(TIM14, LL_TIM_CHANNEL_CH1);
    TIM_OC_InitStruct.OCMode = LL_TIM_OCMODE_PWM1;
    TIM_OC_InitStruct.OCState = LL_TIM_OCSTATE_DISABLE;
    TIM_OC_InitStruct.OCNState = LL_TIM_OCSTATE_DISABLE;
    TIM_OC_InitStruct.CompareValue = 0;
    TIM_OC_InitStruct.OCPolarity = LL_TIM_OCPOLARITY_HIGH;
    LL_TIM_OC_Init(TIM14, LL_TIM_CHANNEL_CH1, &TIM_OC_InitStruct);
    LL_TIM_OC_DisableFast(TIM14, LL_TIM_CHANNEL_CH1);
}

/**
 * @brief  Initializes TIM16 for auxiliary PWM
 * @retval None
 */
static void MX_TIM16_Init(void) {
    LL_TIM_InitTypeDef TIM_InitStruct = {0}; // TIM16 initialization structure
    LL_TIM_OC_InitTypeDef TIM_OC_InitStruct = {0}; // Output compare structure
    LL_TIM_BDTR_InitTypeDef TIM_BDTRInitStruct = {0}; // Break and dead-time structure

    LL_APB1_GRP2_EnableClock(LL_APB1_GRP2_PERIPH_TIM16); // Enable TIM16 clock

    // Configure TIM16 for PWM
    TIM_InitStruct.Prescaler = 47;
    TIM_InitStruct.CounterMode = LL_TIM_COUNTERMODE_UP;
    TIM_InitStruct.Autoreload = 1999;
    TIM_InitStruct.ClockDivision = LL_TIM_CLOCKDIVISION_DIV1;
    TIM_InitStruct.RepetitionCounter = 0;
    LL_TIM_Init(TIM16, &TIM_InitStruct);
    LL_TIM_DisableARRPreload(TIM16);

    LL_TIM_OC_EnablePreload(TIM16, LL_TIM_CHANNEL_CH1);
    TIM_OC_InitStruct.OCMode = LL_TIM_OCMODE_PWM1;
    TIM_OC_InitStruct.OCState = LL_TIM_OCSTATE_DISABLE;
    TIM_OC_InitStruct.OCNState = LL_TIM_OCSTATE_DISABLE;
    TIM_OC_InitStruct.CompareValue = 0;
    TIM_OC_InitStruct.OCPolarity = LL_TIM_OCPOLARITY_HIGH;
    TIM_OC_InitStruct.OCNPolarity = LL_TIM_OCPOLARITY_HIGH;
    TIM_OC_InitStruct.OCIdleState = LL_TIM_OCIDLESTATE_LOW;
    TIM_OC_InitStruct.OCNIdleState = LL_TIM_OCIDLESTATE_LOW;
    LL_TIM_OC_Init(TIM16, LL_TIM_CHANNEL_CH1, &TIM_OC_InitStruct);
    LL_TIM_OC_DisableFast(TIM16, LL_TIM_CHANNEL_CH1);

    TIM_BDTRInitStruct.OSSRState = LL_TIM_OSSR_DISABLE;
    TIM_BDTRInitStruct.OSSIState = LL_TIM_OSSI_DISABLE;
    TIM_BDTRInitStruct.LockLevel = LL_TIM_LOCKLEVEL_OFF;
    TIM_BDTRInitStruct.DeadTime = 0;
    TIM_BDTRInitStruct.BreakState = LL_TIM_BREAK_DISABLE;
    TIM_BDTRInitStruct.BreakPolarity = LL_TIM_BREAK_POLARITY_HIGH;
    TIM_BDTRInitStruct.AutomaticOutput = LL_TIM_AUTOMATICOUTPUT_DISABLE;
    LL_TIM_BDTR_Init(TIM16, &TIM_BDTRInitStruct);
}

/**
 * @brief  Initializes USART1 for serial communication
 * @retval None
 */
static void MX_USART1_UART_Init(void) {
    LL_USART_InitTypeDef USART_InitStruct = {0}; // USART initialization structure
    LL_GPIO_InitTypeDef GPIO_InitStruct = {0}; // GPIO initialization structure

    LL_APB1_GRP2_EnableClock(LL_APB1_GRP2_PERIPH_USART1); // Enable USART1 clock
    LL_AHB1_GRP1_EnableClock(LL_AHB1_GRP1_PERIPH_GPIOA); // Enable GPIOA clock
    LL_AHB1_GRP1_EnableClock(LL_AHB1_GRP1_PERIPH_GPIOB); // Enable GPIOB clock

    // Configure GPIO pins for USART1 (PB6: TX, PA15: RX)
    GPIO_InitStruct.Pin = LL_GPIO_PIN_6;
    GPIO_InitStruct.Mode = LL_GPIO_MODE_ALTERNATE;
    GPIO_InitStruct.Speed = LL_GPIO_SPEED_FREQ_HIGH;
    GPIO_InitStruct.OutputType = LL_GPIO_OUTPUT_PUSHPULL;
    GPIO_InitStruct.Pull = LL_GPIO_PULL_NO;
    GPIO_InitStruct.Alternate = LL_GPIO_AF_0;
    LL_GPIO_Init(GPIOB, &GPIO_InitStruct);

    GPIO_InitStruct.Pin = LL_GPIO_PIN_15;
    GPIO_InitStruct.Mode = LL_GPIO_MODE_ALTERNATE;
    GPIO_InitStruct.Speed = LL_GPIO_SPEED_FREQ_HIGH;
    GPIO_InitStruct.OutputType = LL_GPIO_OUTPUT_PUSHPULL;
    GPIO_InitStruct.Pull = LL_GPIO_PULL_NO;
    GPIO_InitStruct.Alternate = LL_GPIO_AF_1;
    LL_GPIO_Init(GPIOA, &GPIO_InitStruct);

    // Configure USART1
    USART_InitStruct.BaudRate = 19200;
    USART_InitStruct.DataWidth = LL_USART_DATAWIDTH_8B;
    USART_InitStruct.StopBits = LL_USART_STOPBITS_1;
    USART_InitStruct.Parity = LL_USART_PARITY_NONE;
    USART_InitStruct.TransferDirection = LL_USART_DIRECTION_TX_RX;
    USART_InitStruct.HardwareFlowControl = LL_USART_HWCONTROL_NONE;
    USART_InitStruct.OverSampling = LL_USART_OVERSAMPLING_16;
    LL_USART_Init(USART1, &USART_InitStruct);
    LL_USART_DisableIT_CTS(USART1); // Disable CTS interrupt
    LL_USART_ConfigAsyncMode(USART1); // Configure for asynchronous mode
    LL_USART_Enable(USART1); // Enable USART1
    LL_USART_TransmitData8(USART1, 72); // Transmit initial test byte
}

/**
 * @brief  Enables DMA controller clock
 * @retval None
 */
static void MX_DMA_Init(void) {
    LL_AHB1_GRP1_EnableClock(LL_AHB1_GRP1_PERIPH_DMA1); // Enable DMA1 clock
}

/**
 * @brief  Initializes GPIO pins for motor control and communication
 * @retval None
 */
static void MX_GPIO_Init(void) {
    LL_EXTI_InitTypeDef EXTI_InitStruct = {0}; // EXTI initialization structure
    LL_GPIO_InitTypeDef GPIO_InitStruct = {0}; // GPIO initialization structure

    // Enable GPIO clocks
    LL_AHB1_GRP1_EnableClock(LL_AHB1_GRP1_PERIPH_GPIOF);
    LL_AHB1_GRP1_EnableClock(LL_AHB1_GRP1_PERIPH_GPIOA);
    LL_AHB1_GRP1_EnableClock(LL_AHB1_GRP1_PERIPH_GPIOB);

    // Initialize output pins
    LL_GPIO_ResetOutputPin(LED_GPIO_Port, LED_Pin); // Reset LED pin
    LL_GPIO_ResetOutputPin(RS485_DE_GPIO_Port, RS485_DE_Pin); // Reset RS485 driver enable
    LL_GPIO_SetOutputPin(OC_SEL_GPIO_Port, OC_SEL_Pin); // Set overcurrent select
    LL_GPIO_SetOutputPin(OCTH_STBY2_GPIO_Port, OCTH_STBY2_Pin); // Set standby 2
    LL_GPIO_SetOutputPin(OCTH_STBY1_GPIO_Port, OCTH_STBY1_Pin); // Set standby 1

    // Configure LED pin
    GPIO_InitStruct.Pin = LED_Pin;
    GPIO_InitStruct.Mode = LL_GPIO_MODE_OUTPUT;
    GPIO_InitStruct.Speed = LL_GPIO_SPEED_FREQ_LOW;
    GPIO_InitStruct.OutputType = LL_GPIO_OUTPUT_PUSHPULL;
    GPIO_InitStruct.Pull = LL_GPIO_PULL_NO;
    LL_GPIO_Init(LED_GPIO_Port, &GPIO_InitStruct);

    // Configure overcurrent select pin
    GPIO_InitStruct.Pin = OC_SEL_Pin;
    GPIO_InitStruct.Pull = LL_GPIO_PULL_DOWN;
    LL_GPIO_Init(OC_SEL_GPIO_Port, &GPIO_InitStruct);

    // Configure overcurrent comparator input
    GPIO_InitStruct.Pin = OC_COMP_INT2_Pin;
    GPIO_InitStruct.Mode = LL_GPIO_MODE_INPUT;
    GPIO_InitStruct.Pull = LL_GPIO_PULL_DOWN;
    LL_GPIO_Init(OC_COMP_INT2_GPIO_Port, &GPIO_InitStruct);

    // Configure standby pins
    GPIO_InitStruct.Pin = OCTH_STBY2_Pin;
    GPIO_InitStruct.Mode = LL_GPIO_MODE_OUTPUT;
    GPIO_InitStruct.Pull = LL_GPIO_PULL_DOWN;
    LL_GPIO_Init(OCTH_STBY2_GPIO_Port, &GPIO_InitStruct);

    GPIO_InitStruct.Pin = OCTH_STBY1_Pin;
    LL_GPIO_Init(OCTH_STBY1_GPIO_Port, &GPIO_InitStruct);

    // Configure RS485 driver enable pin
    GPIO_InitStruct.Pin = RS485_DE_Pin;
    GPIO_InitStruct.Pull = LL_GPIO_PULL_NO;
    LL_GPIO_Init(RS485_DE_GPIO_Port, &GPIO_InitStruct);

    // Configure EXTI for encoder Z signal
    LL_SYSCFG_SetEXTISource(LL_SYSCFG_EXTI_PORTF, LL_SYSCFG_EXTI_LINE1);
    LL_GPIO_SetPinPull(M1_ENCODER_Z_GPIO_Port, M1_ENCODER_Z_Pin, LL_GPIO_PULL_NO);
    LL_GPIO_SetPinMode(M1_ENCODER_Z_GPIO_Port, M1_ENCODER_Z_Pin, LL_GPIO_MODE_INPUT);
    EXTI_InitStruct.Line_0_31 = LL_EXTI_LINE_1;
    EXTI_InitStruct.LineCommand = ENABLE;
    EXTI_InitStruct.Mode = LL_EXTI_MODE_IT;
    EXTI_InitStruct.Trigger = LL_EXTI_TRIGGER_RISING;
    LL_EXTI_Init(&EXTI_InitStruct);
}

/**
 * @brief  Error handler function
 * @retval None
 */
void Error_Handler(void) {
    /* USER CODE BEGIN Error_Handler_Debug */
    /* User can add custom error handling here */
    /* USER CODE END Error_Handler_Debug */
}

#ifdef USE_FULL_ASSERT
/**
 * @brief  Reports assert_param errors
 * @param  file: Pointer to the source file name
 * @param  line: Assert error line number
 * @retval None
 */
void assert_failed(uint8_t *file, uint32_t line) {
    /* USER CODE BEGIN 6 */
    /* User can add custom implementation to report file and line */
    /* USER CODE END 6 */
}
#endif /* USE_FULL_ASSERT */

/************************ (C) COPYRIGHT STMicroelectronics *****END OF FILE****/
